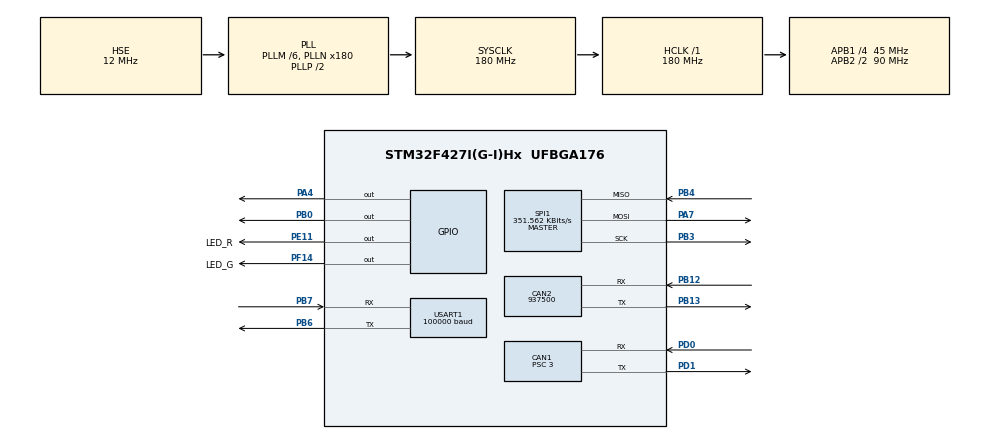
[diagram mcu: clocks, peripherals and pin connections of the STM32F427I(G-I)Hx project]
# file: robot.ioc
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CAN1.BS1=CAN_BS1_11TQ
CAN1.BS2=CAN_BS2_3TQ
CAN1.CalculateBaudRate=1000000
CAN1.CalculateTimeBit=1000
CAN1.CalculateTimeQuantum=66.66666666666666
CAN1.Prescaler=3
CAN2.CalculateBaudRate=937500
CAN2.CalculateTimeBit=1066
CAN2.CalculateTimeQuantum=355.55555555555554
FREERTOS.Tasks01=led_task,24,128,led_task_entry,As weak,NULL,Dynamic,NULL,NULL;can_rx_task,24,128,can_rx_task_entry,As weak,NULL,Dynamic,NULL,NULL;dbus_task,24,128,dbus_task_entry,As weak,NULL,Dynamic,NULL,NULL;chasiss_task,8,128,chasiss_task_entry,As weak,NULL,Dynamic,NULL,NULL;gimbal_task,8,128,gimbal_task_entry,As weak,NULL,Dynamic,NULL,NULL;bmi_task,8,128,bmi_task_entry,As weak,NULL,Dynamic,NULL,NULL
Mcu.Family=STM32F4
Mcu.Name=STM32F427I(G-I)Hx
Mcu.Package=UFBGA176
NVIC.CAN1_RX0_IRQn=true\:6\:0\:true\:false\:true\:true\:true\:true\:true
NVIC.CAN2_RX0_IRQn=true\:6\:0\:true\:false\:true\:true\:true\:true\:true
NVIC.PriorityGroup=NVIC_PRIORITYGROUP_4
NVIC.TIM1_UP_TIM10_IRQn=true\:15\:0\:false\:false\:true\:false\:false\:true\:true
NVIC.TimeBase=TIM1_UP_TIM10_IRQn
NVIC.TimeBaseIP=TIM1
NVIC.USART1_IRQn=true\:7\:0\:true\:false\:true\:true\:true\:true\:true
PA13.Mode=Serial_Wire
PA13.Signal=SYS_JTMS-SWDIO
PA14.Mode=Serial_Wire
PA14.Signal=SYS_JTCK-SWCLK
PA4.Signal=GPIO_Output
PA7.Mode=Full_Duplex_Master
PA7.Signal=SPI1_MOSI
PB0.Signal=GPIO_Output
PB12.Mode=CAN_Activate
PB12.Signal=CAN2_RX
PB13.Mode=CAN_Activate
PB13.Signal=CAN2_TX
PB3.Mode=Full_Duplex_Master
PB3.Signal=SPI1_SCK
PB4.Mode=Full_Duplex_Master
PB4.Signal=SPI1_MISO
PB6.Mode=Asynchronous
PB6.Signal=USART1_TX
PB7.Mode=Asynchronous
PB7.Signal=USART1_RX
PD0.Mode=CAN_Activate
PD0.Signal=CAN1_RX
PD1.Mode=CAN_Activate
PD1.Signal=CAN1_TX
PE11.GPIO_Label=LED_R
PE11.GPIO_ModeDefaultOutputPP=GPIO_MODE_OUTPUT_PP
PE11.GPIO_PuPd=GPIO_PULLUP
PE11.GPIO_Speed=GPIO_SPEED_FREQ_LOW
PE11.PinState=GPIO_PIN_SET
PE11.Signal=GPIO_Output
PF14.GPIO_Label=LED_G
PF14.GPIO_PuPd=GPIO_PULLUP
PF14.PinState=GPIO_PIN_SET
PF14.Signal=GPIO_Output
PH0/OSC_IN.Mode=HSE-External-Oscillator
PH0/OSC_IN.Signal=RCC_OSC_IN
PH1/OSC_OUT.Mode=HSE-External-Oscillator
PH1/OSC_OUT.Signal=RCC_OSC_OUT
ProjectManager.HeapSize=0x200
ProjectManager.StackSize=0x400
ProjectManager.TargetToolchain=MDK-ARM V5.32
RCC.48MHZClocksFreq_Value=90000000
RCC.AHBFreq_Value=180000000
RCC.APB1CLKDivider=RCC_HCLK_DIV4
RCC.APB1Freq_Value=45000000
RCC.APB1TimFreq_Value=90000000
RCC.APB2CLKDivider=RCC_HCLK_DIV2
RCC.APB2Freq_Value=90000000
RCC.APB2TimFreq_Value=180000000
RCC.CortexFreq_Value=180000000
RCC.HCLKFreq_Value=180000000
RCC.HSE_VALUE=12000000
RCC.HSI_VALUE=16000000
RCC.LSE_VALUE=32768
RCC.PLLM=6
RCC.PLLN=180
RCC.PLLSourceVirtual=RCC_PLLSOURCE_HSE
RCC.SYSCLKFreq_VALUE=180000000
RCC.SYSCLKSource=RCC_SYSCLKSOURCE_PLLCLK
RCC.VCOOutputFreq_Value=360000000
SPI1.BaudRatePrescaler=SPI_BAUDRATEPRESCALER_256
SPI1.CalculateBaudRate=351.562 KBits/s
SPI1.Direction=SPI_DIRECTION_2LINES
SPI1.Mode=SPI_MODE_MASTER
SPI1.VirtualType=VM_MASTER
USART1.BaudRate=100000
USART1.VirtualMode=VM_ASYNC
VP_FREERTOS_VS_CMSIS_V2.Mode=CMSIS_V2
VP_SYS_VS_tim1.Mode=TIM1
board=custom

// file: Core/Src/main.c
/* USER CODE BEGIN Header */
/**
  ******************************************************************************
  * @file           : main.c
  * @brief          : Main program body
  ******************************************************************************
  * @attention
  *
  * Copyright (c) 2024 STMicroelectronics.
  * All rights reserved.
  *
  * This software is licensed under terms that can be found in the LICENSE file
  * in the root directory of this software component.
  * If no LICENSE file comes with this software, it is provided AS-IS.
  *
  ******************************************************************************
  */
/* USER CODE END Header */
#include "main.h"
#include "cmsis_os.h"
#include "can.h"
#include "spi.h"
#include "usart.h"
#include "gpio.h"

void SystemClock_Config(void);
void MX_FREERTOS_Init(void);

int main(void)
{

  /* MCU Configuration--------------------------------------------------------*/

  /* Reset of all peripherals, Initializes the Flash interface and the Systick. */
  HAL_Init();

  /* Configure the system clock */
  SystemClock_Config();

  /* Initialize all configured peripherals */
  MX_GPIO_Init();
  MX_USART1_UART_Init();
  MX_CAN1_Init();
  MX_CAN2_Init();
  MX_SPI1_Init();
  /* USER CODE BEGIN 2 */
  can_filter_init();

  /* USER CODE END 2 */

  /* Init scheduler */
  osKernelInitialize();

  /* Call init function for freertos objects (in cmsis_os2.c) */
  MX_FREERTOS_Init();

  /* Start scheduler */
  osKernelStart();

  /* We should never get here as control is now taken by the scheduler */

  /* Infinite loop */
  /* USER CODE BEGIN WHILE */
  while (1)
  {

		//   asdghajhgdajkhgda
    /* USER CODE END WHILE */

  }
}

void SystemClock_Config(void)
{
  RCC_OscInitTypeDef RCC_OscInitStruct = {0};
  RCC_ClkInitTypeDef RCC_ClkInitStruct = {0};

  /** Configure the main internal regulator output voltage
  */
  __HAL_RCC_PWR_CLK_ENABLE();
  __HAL_PWR_VOLTAGESCALING_CONFIG(PWR_REGULATOR_VOLTAGE_SCALE1);

  /** Initializes the RCC Oscillators according to the specified parameters
  * in the RCC_OscInitTypeDef structure.
  */
  RCC_OscInitStruct.OscillatorType = RCC_OSCILLATORTYPE_HSE;
  RCC_OscInitStruct.HSEState = RCC_HSE_ON;
  RCC_OscInitStruct.PLL.PLLState = RCC_PLL_ON;
  RCC_OscInitStruct.PLL.PLLSource = RCC_PLLSOURCE_HSE;
  RCC_OscInitStruct.PLL.PLLM = 6;
  RCC_OscInitStruct.PLL.PLLN = 180;
  RCC_OscInitStruct.PLL.PLLP = RCC_PLLP_DIV2;
  RCC_OscInitStruct.PLL.PLLQ = 4;
  if (HAL_RCC_OscConfig(&RCC_OscInitStruct) != HAL_OK)
  {
    Error_Handler();
  }

  /** Activate the Over-Drive mode
  */
  if (HAL_PWREx_EnableOverDrive() != HAL_OK)
  {
    Error_Handler();
  }

  /** Initializes the CPU, AHB and APB buses clocks
  */
  RCC_ClkInitStruct.ClockType = RCC_CLOCKTYPE_HCLK|RCC_CLOCKTYPE_SYSCLK
                              |RCC_CLOCKTYPE_PCLK1|RCC_CLOCKTYPE_PCLK2;
  RCC_ClkInitStruct.SYSCLKSource = RCC_SYSCLKSOURCE_PLLCLK;
  RCC_ClkInitStruct.AHBCLKDivider = RCC_SYSCLK_DIV1;
  RCC_ClkInitStruct.APB1CLKDivider = RCC_HCLK_DIV4;
  RCC_ClkInitStruct.APB2CLKDivider = RCC_HCLK_DIV2;

  if (HAL_RCC_ClockConfig(&RCC_ClkInitStruct, FLASH_LATENCY_5) != HAL_OK)
  {
    Error_Handler();
  }
}

void HAL_TIM_PeriodElapsedCallback(TIM_HandleTypeDef *htim)
{
  if (htim->Instance == TIM1) {
    HAL_IncTick();
  }
}

void Error_Handler(void)
{
  __disable_irq();
  while (1)
  {
  }
}

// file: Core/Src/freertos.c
/* USER CODE BEGIN Header */
/**
  ******************************************************************************
  * File Name          : freertos.c
  * Description        : Code for freertos applications
  ******************************************************************************
  * @attention
  *
  * Copyright (c) 2024 STMicroelectronics.
  * All rights reserved.
  *
  * This software is licensed under terms that can be found in the LICENSE file
  * in the root directory of this software component.
  * If no LICENSE file comes with this software, it is provided AS-IS.
  *
  ******************************************************************************
  */
/* USER CODE END Header */

#include "main.h"
#include "FreeRTOS.h"
#include "task.h"
#include "cmsis_os.h"

/* Definitions for led_task */
osThreadId_t led_taskHandle;
const osThreadAttr_t led_task_attributes = {
  .name = "led_task",
  .stack_size = 128 * 4,
  .priority = (osPriority_t) osPriorityNormal,
};
/* Definitions for can_rx_task */
osThreadId_t can_rx_taskHandle;
const osThreadAttr_t can_rx_task_attributes = {
  .name = "can_rx_task",
  .stack_size = 128 * 4,
  .priority = (osPriority_t) osPriorityNormal,
};
/* Definitions for dbus_task */
osThreadId_t dbus_taskHandle;
const osThreadAttr_t dbus_task_attributes = {
  .name = "dbus_task",
  .stack_size = 128 * 4,
  .priority = (osPriority_t) osPriorityNormal,
};
/* Definitions for chasiss_task */
osThreadId_t chasiss_taskHandle;
const osThreadAttr_t chasiss_task_attributes = {
  .name = "chasiss_task",
  .stack_size = 128 * 4,
  .priority = (osPriority_t) osPriorityLow,
};
/* Definitions for gimbal_task */
osThreadId_t gimbal_taskHandle;
const osThreadAttr_t gimbal_task_attributes = {
  .name = "gimbal_task",
  .stack_size = 128 * 4,
  .priority = (osPriority_t) osPriorityLow,
};
/* Definitions for bmi_task */
osThreadId_t bmi_taskHandle;
const osThreadAttr_t bmi_task_attributes = {
  .name = "bmi_task",
  .stack_size = 128 * 4,
  .priority = (osPriority_t) osPriorityLow,
};

void led_task_entry(void *argument);
void can_rx_task_entry(void *argument);
void dbus_task_entry(void *argument);
void chasiss_task_entry(void *argument);
void gimbal_task_entry(void *argument);
void bmi_task_entry(void *argument);

void MX_FREERTOS_Init(void); /* (MISRA C 2004 rule 8.1) */

void MX_FREERTOS_Init(void) {

  /* Create the thread(s) */
  /* creation of led_task */
  led_taskHandle = osThreadNew(led_task_entry, NULL, &led_task_attributes);

  /* creation of can_rx_task */
  can_rx_taskHandle = osThreadNew(can_rx_task_entry, NULL, &can_rx_task_attributes);

  /* creation of dbus_task */
  dbus_taskHandle = osThreadNew(dbus_task_entry, NULL, &dbus_task_attributes);

  /* creation of chasiss_task */
  chasiss_taskHandle = osThreadNew(chasiss_task_entry, NULL, &chasiss_task_attributes);

  /* creation of gimbal_task */
  gimbal_taskHandle = osThreadNew(gimbal_task_entry, NULL, &gimbal_task_attributes);

  /* creation of bmi_task */
  bmi_taskHandle = osThreadNew(bmi_task_entry, NULL, &bmi_task_attributes);

}

__weak void led_task_entry(void *argument)
{
  for(;;)
  {
    osDelay(1);
  }
}

__weak void can_rx_task_entry(void *argument)
{
  for(;;)
  {
    osDelay(1);
  }
}

__weak void dbus_task_entry(void *argument)
{
  for(;;)
  {
    osDelay(1);
  }
}

__weak void chasiss_task_entry(void *argument)
{
  for(;;)
  {
    osDelay(1);
  }
}

__weak void gimbal_task_entry(void *argument)
{
  for(;;)
  {
    osDelay(1);
  }
}

__weak void bmi_task_entry(void *argument)
{
  for(;;)
  {
    osDelay(1);
  }
}
